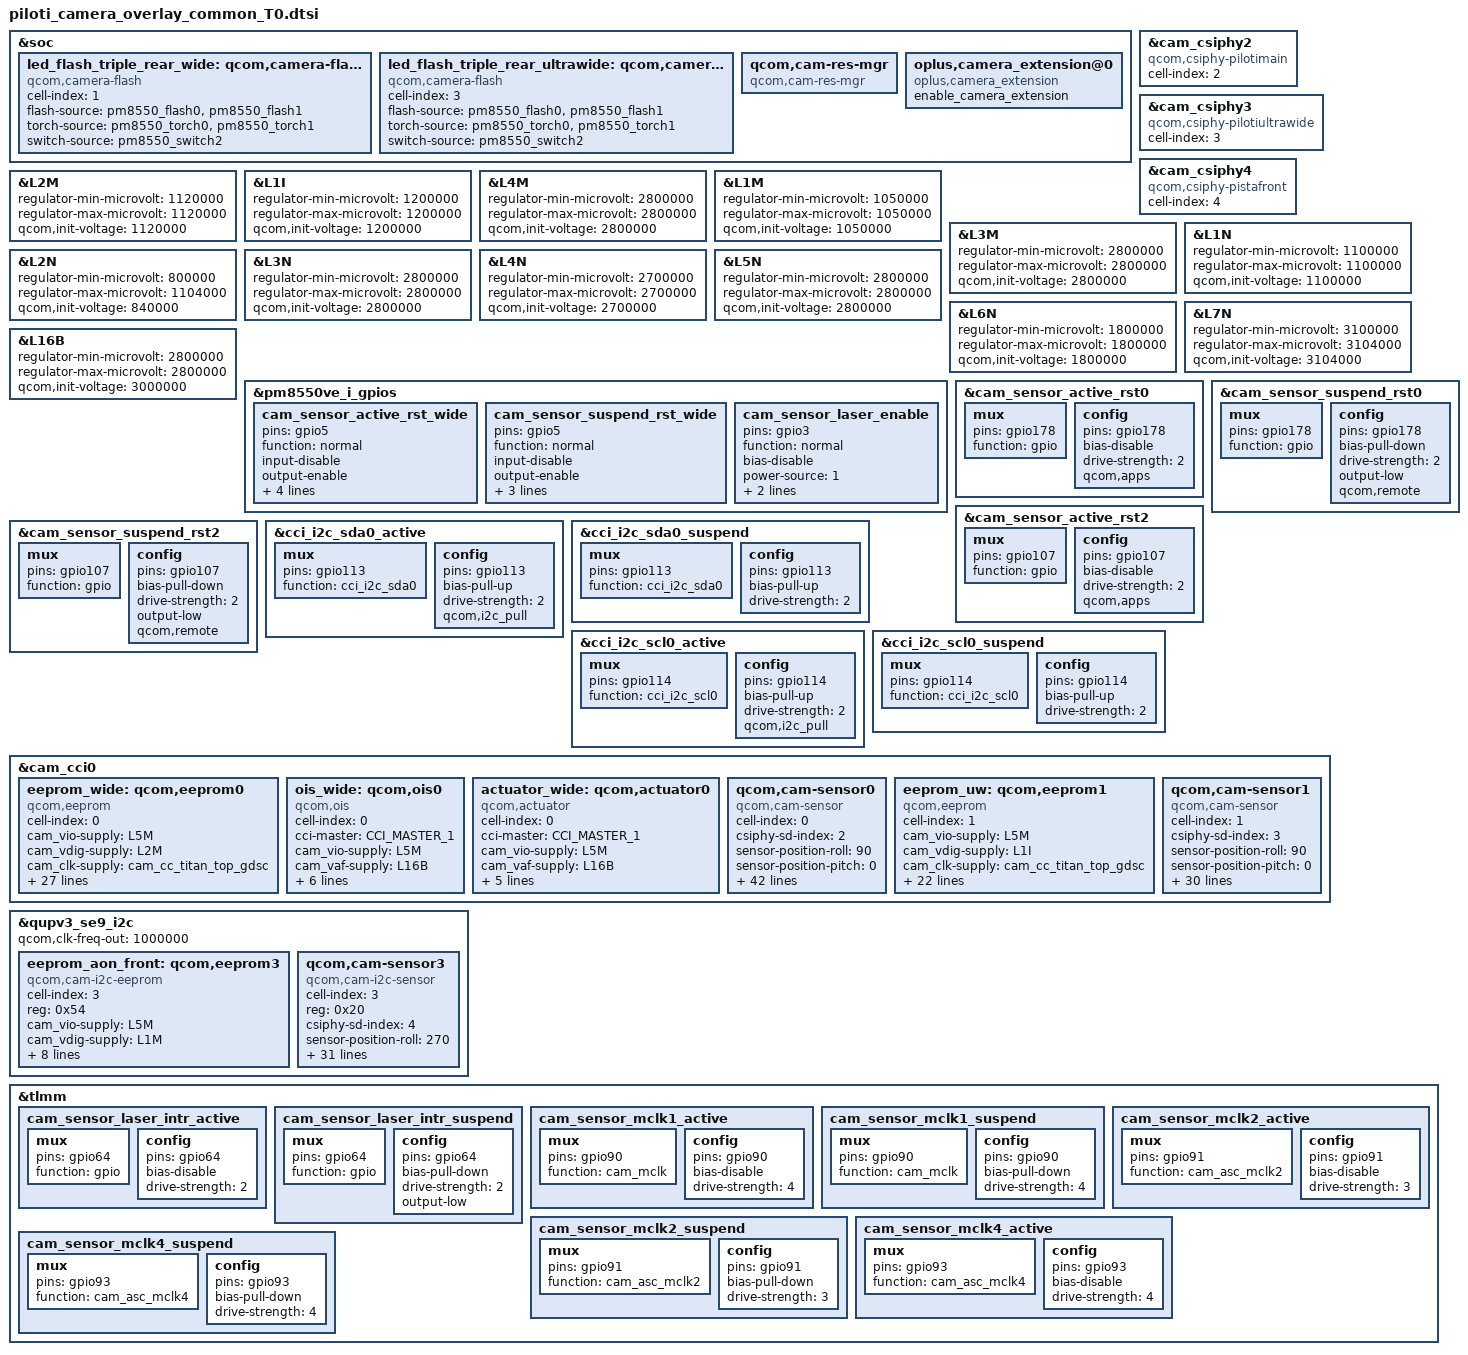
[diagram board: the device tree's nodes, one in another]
#include <dt-bindings/msm-camera.h>
#include "ftm_camera_settings.dtsi"

&soc {
	led_flash_triple_rear_wide: qcom,camera-flash1 {
		cell-index = <1>;
		compatible = "qcom,camera-flash";
		flash-source = <&pm8550_flash0 &pm8550_flash1>;
		torch-source = <&pm8550_torch0 &pm8550_torch1>;
		switch-source = <&pm8550_switch2>;
		status = "ok";
	};

	led_flash_triple_rear_ultrawide: qcom,camera-flash3 {
		cell-index = <3>;
		compatible = "qcom,camera-flash";
		flash-source = <&pm8550_flash0 &pm8550_flash1>;
		torch-source = <&pm8550_torch0 &pm8550_torch1>;
		switch-source = <&pm8550_switch2>;
		status = "ok";
	};
/*
	led_flash_asc_rear: qcom,camera-flash4 {
		cell-index = <4>;
		compatible = "qcom,camera-flash";
		flash-source = <&pm8550_flash0 &pm8550_flash1>;
		torch-source = <&pm8550_torch0 &pm8550_torch1>;
		switch-source = <&pm8550_switch2>;
		status = "ok";
	};

	led_flash_rear_aux: qcom,camera-flash5 {
		cell-index = <5>;
		compatible = "qcom,camera-flash";
		flash-source = <&pm8550_flash0 &pm8550_flash1>;
		torch-source = <&pm8550_torch0 &pm8550_torch1>;
		switch-source = <&pm8550_switch2>;
		status = "ok";
	};
*/
	qcom,cam-res-mgr {
		compatible = "qcom,cam-res-mgr";
		status = "ok";
	};

	oplus,camera_extension@0 {
		compatible = "oplus,camera_extension";
		enable_camera_extension;
		status = "ok";
	};
};

&cam_csiphy2{
        cell-index = <2>;
        compatible = "qcom,csiphy-pilotimain", "qcom,csiphy";
};


&cam_csiphy3{
        cell-index = <3>;
        compatible = "qcom,csiphy-pilotiultrawide", "qcom,csiphy";
};


&cam_csiphy4{
	cell-index = <4>;
	compatible = "qcom,csiphy-pistafront", "qcom,csiphy";
};

&L2M {
  regulator-min-microvolt = <1120000>;
  regulator-max-microvolt = <1120000>;
  qcom,init-voltage = <1120000>;
};

&L1I {
  regulator-min-microvolt = <1200000>;
  regulator-max-microvolt = <1200000>;
  qcom,init-voltage = <1200000>;
};

&L4M {
  regulator-min-microvolt = <2800000>;
  regulator-max-microvolt = <2800000>;
  qcom,init-voltage = <2800000>;
};

&L1M {
  regulator-min-microvolt = <1050000>;
  regulator-max-microvolt = <1050000>;
  qcom,init-voltage = <1050000>;
};

&L3M {
  regulator-min-microvolt = <2800000>;
  regulator-max-microvolt = <2800000>;
  qcom,init-voltage = <2800000>;
};

&L1N {
  regulator-min-microvolt = <1100000>;
  regulator-max-microvolt = <1100000>;
  qcom,init-voltage = <1100000>;
};

&L2N {
  regulator-min-microvolt = <800000>;
  regulator-max-microvolt = <1104000>;
  qcom,init-voltage = <840000>;
};

&L3N {
  regulator-min-microvolt = <2800000>;
  regulator-max-microvolt = <2800000>;
  qcom,init-voltage = <2800000>;
};

&L4N {
  regulator-min-microvolt = <2700000>;
  regulator-max-microvolt = <2700000>;
  qcom,init-voltage = <2700000>;
};

&L5N {
  regulator-min-microvolt = <2800000>;
  regulator-max-microvolt = <2800000>;
  qcom,init-voltage = <2800000>;
};

&L6N {
  regulator-min-microvolt = <1800000>;
  regulator-max-microvolt = <1800000>;
  qcom,init-voltage = <1800000>;
};

&L7N {
  regulator-min-microvolt = <3100000>;
  regulator-max-microvolt = <3104000>;
  qcom,init-voltage = <3104000>;
};

&L16B {
  regulator-min-microvolt = <2800000>;
  regulator-max-microvolt = <2800000>;
  qcom,init-voltage = <3000000>;
};

&pm8550ve_i_gpios {
	cam_sensor_active_rst_wide: cam_sensor_active_rst_wide {
		pins = "gpio5";
		function = "normal";
		input-disable;
		output-enable;
		bias-disable;
		output-low;
		power-source = <1>;
		qcom,drive-strength = <2>;
	};

	cam_sensor_suspend_rst_wide: cam_sensor_suspend_rst_wide {
		pins = "gpio5";
		function = "normal";
		input-disable;
		output-enable;
		bias-pull-down;
		power-source = <1>;
		qcom,drive-strength = <2>;
	};

	cam_sensor_laser_enable: cam_sensor_laser_enable {
 		pins = "gpio3";
		function = "normal";
		bias-disable;
		power-source = <1>;
		output-high;
		qcom,drive-strength = <2>;
 	};
};

&cam_sensor_active_rst0 {
	mux {
		pins = "gpio178";
		function = "gpio";
	};

	config {
		pins = "gpio178";
		bias-disable; /* No PULL */
		drive-strength = <2>; /* 2 MA */
		qcom,apps;
	};
};

&cam_sensor_suspend_rst0 {
	mux {
		pins = "gpio178";
		function = "gpio";
	};

	config {
		pins = "gpio178";
		bias-pull-down; /* PULL DOWN */
		drive-strength = <2>; /* 2 MA */
		output-low;
		qcom,remote;
	};
};

&cam_sensor_active_rst2 {
		mux {
			pins = "gpio107";
			function = "gpio";
		};

		config {
			pins = "gpio107";
			bias-disable; /* No PULL */
			drive-strength = <2>; /* 2 MA */
			qcom,apps;
		};
};

&cam_sensor_suspend_rst2 {
		mux {
			pins = "gpio107";
			function = "gpio";
		};

		config {
			pins = "gpio107";
			bias-pull-down; /* PULL DOWN */
			drive-strength = <2>; /* 2 MA */
			output-low;
			qcom,remote;
		};
};

&cci_i2c_sda0_active {
	mux {
		/* CLK, DATA */
		pins = "gpio113";
		function = "cci_i2c_sda0";
	};

	config {
		pins = "gpio113";
		bias-pull-up; /* PULL UP*/
		drive-strength = <2>; /* 2 MA */
		qcom,i2c_pull;
	};
};

&cci_i2c_sda0_suspend {
	mux {
		/* CLK, DATA */
		pins = "gpio113";
		function = "cci_i2c_sda0";
	};

	config {
		pins = "gpio113";
		bias-pull-up; /* PULL UP */
		drive-strength = <2>; /* 2 MA */
	};
};

&cci_i2c_scl0_active {
	mux {
		/* CLK, DATA */
		pins = "gpio114";
		function = "cci_i2c_scl0";
	};

	config {
		pins = "gpio114";
		bias-pull-up; /* PULL UP*/
		drive-strength = <2>; /* 2 MA */
		qcom,i2c_pull;
	};
};

&cci_i2c_scl0_suspend {
	mux {
		/* CLK, DATA */
		pins = "gpio114";
		function = "cci_i2c_scl0";
	};

	config {
		pins = "gpio114";
		bias-pull-up; /* PULL DOWN */
		drive-strength = <2>; /* 2 MA */
	};
};

&cam_cci0 {

	eeprom_wide: qcom,eeprom0 {
		cell-index = <0>;
		compatible = "qcom,eeprom";
		cam_vio-supply = <&L5M>;
		cam_vdig-supply = <&L2M>;
		cam_clk-supply = <&cam_cc_titan_top_gdsc>;
		cam_vana-supply = <&L4M>;
		cam_vaf-supply = <&L16B>;
		cam_v_custom1-supply = <&L6M>;
		regulator-names = "cam_vio", "cam_vdig", "cam_clk", "cam_vana",
			"cam_vaf", "cam_v_custom1";
		rgltr-cntrl-support;
		rgltr-min-voltage = <1800000 1120000 0 2800000 2800000 1800000>;
		rgltr-max-voltage = <1800000 1120000 0 2800000 2800000 1800000>;
		rgltr-load-current = <300000 1200000 0 300000 300000 300000>;
		gpio-no-mux = <0>;
		pinctrl-names = "cam_default", "cam_suspend";
		pinctrl-0 = <&cam_sensor_mclk1_active
				 &cam_sensor_active_rst_wide>;
		pinctrl-1 = <&cam_sensor_mclk1_suspend
				 &cam_sensor_suspend_rst_wide>;
		gpios = <&tlmm 90 0>,
			<&pm8550ve_i_gpios 5 0>;
		gpio-reset = <1>;
		gpio-req-tbl-num = <0 1>;
		gpio-req-tbl-flags = <1 0>;
		gpio-req-tbl-label = "CAMIF_MCLK1",
					"CAM_RESET1";
		cci-master = <CCI_MASTER_1>;
		clocks = <&cambistmclkcc CAM_BIST_MCLK_CC_MCLK1_CLK>;
		clock-names = "cam_clk";
		clock-cntl-level = "nominal";
		clock-rates = <19200000>;
		status = "ok";
	};

	ois_wide: qcom,ois0 {
		cell-index = <0>;
		compatible = "qcom,ois";
		cci-master = <CCI_MASTER_1>;
		cam_vio-supply = <&L5M>;
		cam_vaf-supply = <&L16B>;
		cam_clk-supply = <&cam_cc_titan_top_gdsc>;
		regulator-names = "cam_vio","cam_vaf", "cam_clk";
		rgltr-cntrl-support;
		rgltr-min-voltage = <1800000 2800000 0>;
		rgltr-max-voltage = <1800000 2800000 0>;
		rgltr-load-current = <300000 300000 0>;
		// ois_gyro,position=<3>;
		// ois_gyro,type=<3>;
		// ois,type=<0>;
		// //ois,name="bu63169";//??
		// ois_module,vendor=<1>;
		// ois_actuator,vednor=<2>;
		// ois,fw=<1>;
		status = "ok";
	};

	actuator_wide: qcom,actuator0 {
		cell-index = <0>;
		compatible = "qcom,actuator";
		cci-master = <CCI_MASTER_1>;
		cam_vio-supply = <&L5M>;
		cam_vaf-supply = <&L16B>;
		regulator-names = "cam_vio", "cam_vaf";
		rgltr-cntrl-support;
		rgltr-min-voltage = <1800000 2800000>;
		rgltr-max-voltage = <1800000 2800000>;
		rgltr-load-current = <300000 300000>;
		// reactive-ctrl-support;
		// //                       reg_addr   addr_type   reg_data    data_type   delay       data_mask
		// reactive-reg-setting = < 0x02       1           0x00        1           2800        0x00 >;
		// is_update_pid;
		// actuator,name = "ak7316";
		// actuator_function = <1>;
		// cci_client_sid = <0x18>;
		// sds-lock-support;
		// //                       reg_addr   addr_type   reg_data    data_type   delay       data_mask
		// sds-lock-reg-setting = < 0x02           1         0x40        1          10            0x00 >,
		//                        < 0x02           1         0x40        1          10            0x00 >,
		//                        < 0x00           1         0x80        1          5             0x00 >,
		//                        < 0x02           1         0x00        1          5             0x00 >;
		status = "ok";
	};

	// wide camera
	qcom,cam-sensor0 {
		cell-index = <0>;
		compatible = "qcom,cam-sensor";
		csiphy-sd-index = <2>;
		sensor-position-roll = <90>;
		sensor-position-pitch = <0>;
		sensor-position-yaw = <180>;
		eeprom-src = <&eeprom_wide>;
		ois-src = <&ois_wide>;
		actuator-src = <&actuator_wide>;
		led-flash-src = <&led_flash_triple_rear_wide>;
		cam_vio-supply = <&L5M>;
		cam_vdig-supply = <&L2M>;
		cam_clk-supply = <&cam_cc_titan_top_gdsc>;
		cam_vana-supply = <&L4M>;
		cam_vaf-supply = <&L16B>;
		cam_v_custom1-supply = <&L6M>;
		regulator-names = "cam_vio", "cam_vdig", "cam_clk", "cam_vana",
			"cam_vaf", "cam_v_custom1";
		rgltr-cntrl-support;
		rgltr-min-voltage = <1800000 1120000 0 2800000 2800000 1800000>;
		rgltr-max-voltage = <1800000 1120000 0 2800000 2800000 1800000>;
		rgltr-load-current = <300000 1200000 0 300000 300000 300000>;
		gpio-no-mux = <0>;
		pinctrl-names = "cam_default", "cam_suspend";
		pinctrl-0 = <&cam_sensor_mclk1_active
				&cam_sensor_active_rst_wide>;
		pinctrl-1 = <&cam_sensor_mclk1_suspend
				&cam_sensor_suspend_rst_wide>;
		gpios = <&tlmm 90 0>,
			<&pm8550ve_i_gpios 5 0>;
		gpio-reset = <1>;
		gpio-req-tbl-num = <0 1>;
		gpio-req-tbl-flags = <1 0>;
		gpio-req-tbl-label = "CAMIF_MCLK1",
					"CAM_RESET1";
		cci-master = <CCI_MASTER_1>;
		clocks = <&cambistmclkcc CAM_BIST_MCLK_CC_MCLK1_CLK>;
		clock-names = "cam_clk";
		clock-cntl-level = "nominal";
		clock-rates = <19200000>;
		is-support-laser = <1>;
		enable_qsc_write_in_advance = <1>;
		qsc_reg_addr = <0x2210>;
		eeprom_slave_addr = <0xA0>;
		qsc_data_size = <3072>;
		write_qsc_addr = <0x1000>;
		//sensor_setting_id = <13>;
		ftm_setting_compatible = <'R' 0x0016 2 2 0x0896>; // expect camera_0016_0906
		status = "ok";
	};

	eeprom_uw: qcom,eeprom1 {
		cell-index = <1>;
		compatible = "qcom,eeprom";
		cam_vio-supply = <&L5M>;
		cam_vdig-supply = <&L1I>;
		cam_clk-supply = <&cam_cc_titan_top_gdsc>;
		cam_vana-supply = <&L3M>;
		regulator-names = "cam_vio", "cam_vdig","cam_clk", "cam_vana";
		rgltr-cntrl-support;
		rgltr-min-voltage = <1800000 1200000 0 2800000>;
		rgltr-max-voltage = <1800000 1200000 0 2800000>;
		rgltr-load-current = <300000 1200000 0 300000 >;
		gpio-no-mux = <0>;
		pinctrl-names = "cam_default", "cam_suspend";
		pinctrl-0 = <&cam_sensor_mclk2_active
				&cam_sensor_active_rst0>;
		pinctrl-1 = <&cam_sensor_mclk2_suspend
				&cam_sensor_suspend_rst0>;
		gpios = <&tlmm 91 0>,
			<&tlmm 178 0>;
		gpio-reset = <1>;
		gpio-req-tbl-num = <0 1>;
		gpio-req-tbl-flags = <1 0>;
		gpio-req-tbl-label = "CAMIF_MCLK2",
					"CAM_RESET0";
		cci-master = <CCI_MASTER_0>;
		clocks = <&cambistmclkcc CAM_BIST_MCLK_CC_MCLK2_CLK>;
		clock-names = "cam_clk";
		clock-cntl-level = "nominal";
		clock-rates = <19200000>;
		status = "ok";
	};

	// ultrawide camera
	qcom,cam-sensor1 {
		cell-index = <1>;
		compatible = "qcom,cam-sensor";
		csiphy-sd-index = <3>;
		sensor-position-roll = <90>;
		sensor-position-pitch = <0>;
		sensor-position-yaw = <180>;
		eeprom-src = <&eeprom_uw>;
		led-flash-src = <&led_flash_triple_rear_ultrawide>;
		cam_vio-supply = <&L5M>;
		cam_vdig-supply = <&L1I>;
		cam_clk-supply = <&cam_cc_titan_top_gdsc>;
		cam_vana-supply = <&L3M>;
		regulator-names = "cam_vio", "cam_vdig","cam_clk", "cam_vana";
		rgltr-cntrl-support;
		rgltr-min-voltage = <1800000 1200000 0 2800000>;
		rgltr-max-voltage = <1800000 1200000 0 2800000>;
		rgltr-load-current = <300000 1200000 0 300000 >;
		gpio-no-mux = <0>;
		pinctrl-names = "cam_default", "cam_suspend";
		pinctrl-0 = <&cam_sensor_mclk2_active
				&cam_sensor_active_rst0>;
		pinctrl-1 = <&cam_sensor_mclk2_suspend
				&cam_sensor_suspend_rst0>;
		gpios = <&tlmm 91 0>,
			<&tlmm 178 0>;
		gpio-reset = <1>;
		gpio-req-tbl-num = <0 1>;
		gpio-req-tbl-flags = <1 0>;
		gpio-req-tbl-label = "CAMIF_MCLK2",
					"CAM_RESET0";
		cci-master = <CCI_MASTER_0>;
		clocks = <&cambistmclkcc CAM_BIST_MCLK_CC_MCLK2_CLK>;
		clock-names = "cam_clk";
		clock-cntl-level = "nominal";
		clock-rates = <19200000>;
		ftm_setting_compatible = <'R' 0x0000 1 2 0x5608>;
		//ftm_setting_compatible = <'W' 0xFCFC 2 2 0x4000
		//			  'R' 0x0016 2 2 0x0355>; // expect camera_0000_0355
		status = "ok";
		is_need_framedrop = <1>;
	};

};

&qupv3_se9_i2c {
	status = "ok";
	// qcom,high-perf;
	qcom,clk-freq-out = <1000000>;
	// qcom,pm-ctrl-client;

	eeprom_aon_front: qcom,eeprom3 {
		cell-index = <3>;
		reg = <0x54>;
		compatible = "qcom,cam-i2c-eeprom";
		cam_vio-supply = <&L5M>;
		cam_vdig-supply = <&L1M>;
		cam_clk-supply = <&cam_cc_titan_top_gdsc>;
		cam_vana-supply = <&L3M>;
		regulator-names = "cam_vio", "cam_vdig","cam_clk", "cam_vana";
		rgltr-cntrl-support;
		rgltr-min-voltage = <1800000 1050000 0 2800000>;
		rgltr-max-voltage = <1800000 1050000 0 2800000>;
		rgltr-load-current = <300000 600000 0  300000>;
		status = "ok";
	};

	// front camera
	qcom,cam-sensor3 {
		cell-index = <3>;
		reg = <0x20>;
		compatible = "qcom,cam-i2c-sensor";
		csiphy-sd-index = <4>;
		sensor-position-roll = <270>;
		sensor-position-pitch = <0>;
		sensor-position-yaw = <180>;
		eeprom-src = <&eeprom_aon_front>;
		cam_vio-supply = <&L5M>;
		cam_vdig-supply = <&L1M>;
		cam_clk-supply = <&cam_cc_titan_top_gdsc>;
		cam_vana-supply = <&L3M>;
		regulator-names = "cam_vio", "cam_vdig","cam_clk", "cam_vana";
		rgltr-cntrl-support;
		aon-camera-id = <AON_CAM1>;
		rgltr-min-voltage = <1800000 1050000 0 2800000>;
		rgltr-max-voltage = <1800000 1050000 0 2900000>;
		rgltr-load-current = <300000 600000 0  300000>;
		gpio-no-mux = <0>;
		pinctrl-names = "cam_default", "cam_suspend";
		pinctrl-0 = <&cam_sensor_mclk4_active
				 &cam_sensor_active_rst4>;
		pinctrl-1 = <&cam_sensor_mclk4_suspend
				 &cam_sensor_suspend_rst4>;
		gpios = <&tlmm 93 0>,
			<&tlmm 7 0>;
		gpio-reset = <1>;
		gpio-req-tbl-num = <0 1>;
		gpio-req-tbl-flags = <1 0>;
		gpio-req-tbl-label = "CAMIF_MCLK4",
					"CAM_RESET4";
		clocks = <&cambistmclkcc CAM_BIST_MCLK_CC_MCLK4_CLK>;
		clock-names = "cam_clk";
		clock-cntl-level = "nominal";
		clock-rates = <19200000>;
		swremosaic_sensor_id = <0x0471>;
		ftm_setting_compatible = <'R' 0x0016 2 2 0x0615
					  'R' 0x0016 2 2 0x0471
					  'W' 0x0A02 2 1 0x7F
					  'W' 0x0A00 2 1 0x01
					  'R' 0x0A1F 2 1 0x00B4>; // expect camera_0016_0615_0A1F_0034 camera_0016_0615_0A1F_0038 or camera_0016_0615_0A1F_00B4 camera_0016_0471_0A1F_0000
		status = "ok";
	};
};

&tlmm {

	cam_sensor_laser_intr_active:cam_sensor_laser_intr_active {
		mux {
			pins = "gpio64";
			function = "gpio";
		};

		config {
			pins = "gpio64";
			bias-disable; /* No PULL */
			drive-strength = <2>; /* 2 MA */
		};
	};

	cam_sensor_laser_intr_suspend: cam_sensor_laser_intr_suspend {
		mux {
			pins = "gpio64";
			function = "gpio";
		};

		config {
			pins = "gpio64";
			bias-pull-down; /* PULL DOWN */
			drive-strength = <2>; /* 2 MA */
			output-low;
		};
	};

	cam_sensor_mclk1_active {
		/* MCLK1 */
		mux {
			pins = "gpio90";
			function = "cam_mclk";
		};

		config {
			pins = "gpio90";
			bias-disable; /* No PULL */
			drive-strength = <4>; /* 4 MA */
		};
	};

	cam_sensor_mclk1_suspend {
		/* MCLK1 */
		mux {
			pins = "gpio90";
			function = "cam_mclk";
		};

		config {
			pins = "gpio90";
			bias-pull-down; /* PULL DOWN */
			drive-strength = <4>; /* 4 MA */
		};
	};

        cam_sensor_mclk2_active {
                /* MCLK2 */
                mux {
                        pins = "gpio91";
                        function = "cam_asc_mclk2";
                };

                config {
                        pins = "gpio91";
                        bias-disable; /* No PULL */
                        drive-strength = <3>; /* 3 MA */
                };
        };

        cam_sensor_mclk2_suspend {
                /* MCLK2 */
                mux {
                        pins = "gpio91";
                        function = "cam_asc_mclk2";
                };

                config {
                        pins = "gpio91";
                        bias-pull-down; /* PULL DOWN */
                        drive-strength = <3>; /* 3 MA */
                };
        };

        cam_sensor_mclk4_active {
                /* MCLK4 */
                mux {
                        pins = "gpio93";
                        function = "cam_asc_mclk4";
                };

                config {
                        pins = "gpio93";
                        bias-disable; /* No PULL */
                        drive-strength = <4>; /* 4 MA */
                };
        };

        cam_sensor_mclk4_suspend {
                /* MCLK4 */
                mux {
                        pins = "gpio93";
                        function = "cam_asc_mclk4";
                };

                config {
                        pins = "gpio93";
                        bias-pull-down; /* PULL DOWN */
                        drive-strength = <4>; /* 4 MA */
                };
        };
};
